# CC3200 register map
Vendor: Texas Instruments; Series: SimpleLink; File version: 1.0
CPU: CM4 r0p1, little endian, MPU, no FPU, 3 interrupt priority bits
Registers are 32-bit, read-write, reset 0x0 unless marked. A register's access mark holds for its fields unless they carry their own. Offsets are from the block's base; [hi:lo] are bit positions; {n}, {i} and the like mark numbered series.

## MMCHS — SDHOST
Base 0x44010000
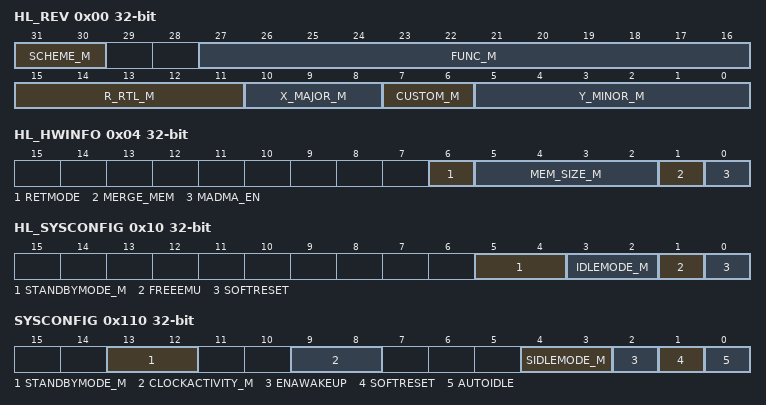
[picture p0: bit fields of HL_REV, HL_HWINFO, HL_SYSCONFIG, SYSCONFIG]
0x00 HL_REV — MMCHS_HL_REV
  [31:30] SCHEME_M — MMCHS_HL_REV
  [27:16] FUNC_M — MMCHS_HL_REV
  [15:11] R_RTL_M — MMCHS_HL_REV
  [10:8] X_MAJOR_M — MMCHS_HL_REV
  [7:6] CUSTOM_M — MMCHS_HL_REV
  [5:0] Y_MINOR_M — MMCHS_HL_REV
0x04 HL_HWINFO — MMCHS_HL_HWINFO
  [6] RETMODE — MMCHS_HL_HWINFO
  [5:2] MEM_SIZE_M — MMCHS_HL_HWINFO
  [1] MERGE_MEM — MMCHS_HL_HWINFO
  [0] MADMA_EN — MMCHS_HL_HWINFO
0x10 HL_SYSCONFIG — MMCHS_HL_SYSCONFIG
  [5:4] STANDBYMODE_M — MMCHS_HL_SYSCONFIG
  [3:2] IDLEMODE_M — MMCHS_HL_SYSCONFIG
  [1] FREEEMU — MMCHS_HL_SYSCONFIG
  [0] SOFTRESET — MMCHS_HL_SYSCONFIG
0x110 SYSCONFIG — MMCHS_SYSCONFIG
  [13:12] STANDBYMODE_M — MMCHS_SYSCONFIG
  [9:8] CLOCKACTIVITY_M — MMCHS_SYSCONFIG
  [4:3] SIDLEMODE_M — MMCHS_SYSCONFIG
  [2] ENAWAKEUP — MMCHS_SYSCONFIG
  [1] SOFTRESET — MMCHS_SYSCONFIG
  [0] AUTOIDLE — MMCHS_SYSCONFIG
0x114 SYSSTATUS — MMCHS_SYSSTATUS
  [0] RESETDONE
0x124 CSRE — MMCHS_CSRE
  [31:0] CSRE_M
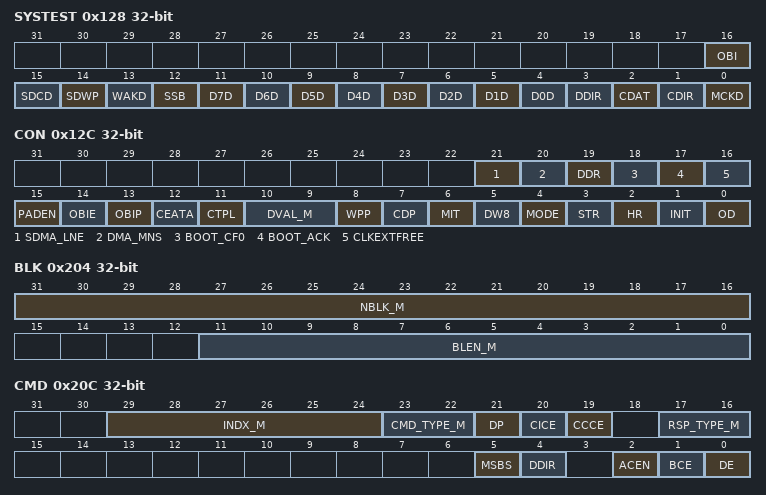
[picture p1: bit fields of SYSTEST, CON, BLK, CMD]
0x128 SYSTEST — MMCHS_SYSTEST
  [16] OBI — MMCHS_SYSTEST
  [15] SDCD — MMCHS_SYSTEST
  [14] SDWP — MMCHS_SYSTEST
  [13] WAKD — MMCHS_SYSTEST
  [12] SSB — MMCHS_SYSTEST
  [n+4] D{n}D (n=0..7) — MMCHS_SYSTEST
  [3] DDIR — MMCHS_SYSTEST
  [2] CDAT — MMCHS_SYSTEST
  [1] CDIR — MMCHS_SYSTEST
  [0] MCKD — MMCHS_SYSTEST
0x12C CON — MMCHS_CON
  [21] SDMA_LNE — MMCHS_CON
  [20] DMA_MNS — MMCHS_CON
  [19] DDR — MMCHS_CON
  [18] BOOT_CF0 — MMCHS_CON
  [17] BOOT_ACK — MMCHS_CON
  [16] CLKEXTFREE — MMCHS_CON
  [15] PADEN — MMCHS_CON
  [14] OBIE — MMCHS_CON
  [13] OBIP — MMCHS_CON
  [12] CEATA — MMCHS_CON
  [11] CTPL — MMCHS_CON
  [10:9] DVAL_M — MMCHS_CON
  [8] WPP — MMCHS_CON
  [7] CDP — MMCHS_CON
  [6] MIT — MMCHS_CON
  [5] DW8 — MMCHS_CON
  [4] MODE — MMCHS_CON
  [3] STR — MMCHS_CON
  [2] HR — MMCHS_CON
  [1] INIT — MMCHS_CON
  [0] OD — MMCHS_CON
0x130 PWCNT — MMCHS_PWCNT
  [15:0] PWRCNT_M
0x204 BLK — MMCHS_BLK
  [31:16] NBLK_M — MMCHS_BLK
  [11:0] BLEN_M — MMCHS_BLK
0x208 ARG — MMCHS_ARG
  [31:0] ARG_M
0x20C CMD — MMCHS_CMD
  [29:24] INDX_M — MMCHS_CMD
  [23:22] CMD_TYPE_M — MMCHS_CMD
  [21] DP — MMCHS_CMD
  [20] CICE — MMCHS_CMD
  [19] CCCE — MMCHS_CMD
  [17:16] RSP_TYPE_M — MMCHS_CMD
  [5] MSBS — MMCHS_CMD
  [4] DDIR — MMCHS_CMD
  [2] ACEN — MMCHS_CMD
  [1] BCE — MMCHS_CMD
  [0] DE — MMCHS_CMD
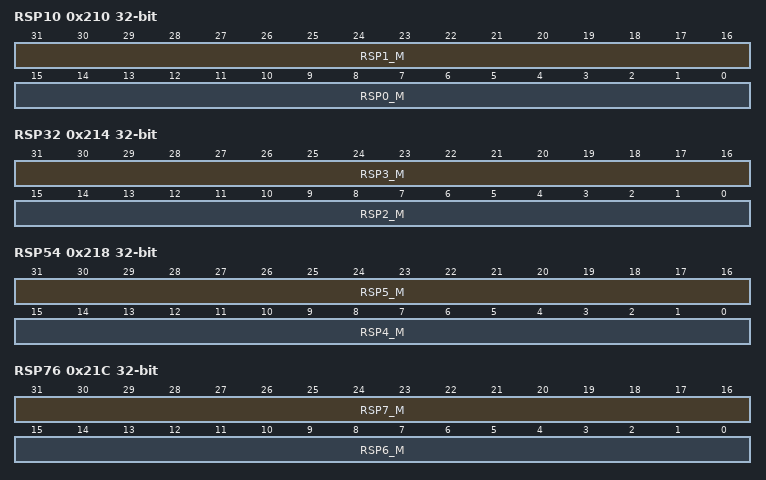
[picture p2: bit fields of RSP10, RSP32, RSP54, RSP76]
0x210 RSP10 — MMCHS_RSP10
  [31:16] RSP1_M — MMCHS_RSP10
  [15:0] RSP0_M — MMCHS_RSP10
0x214 RSP32 — MMCHS_RSP32
  [31:16] RSP3_M — MMCHS_RSP32
  [15:0] RSP2_M — MMCHS_RSP32
0x218 RSP54 — MMCHS_RSP54
  [31:16] RSP5_M — MMCHS_RSP54
  [15:0] RSP4_M — MMCHS_RSP54
0x21C RSP76 — MMCHS_RSP76
  [31:16] RSP7_M — MMCHS_RSP76
  [15:0] RSP6_M — MMCHS_RSP76
0x220 DATA — MMCHS_DATA
  [31:0] DATA_M
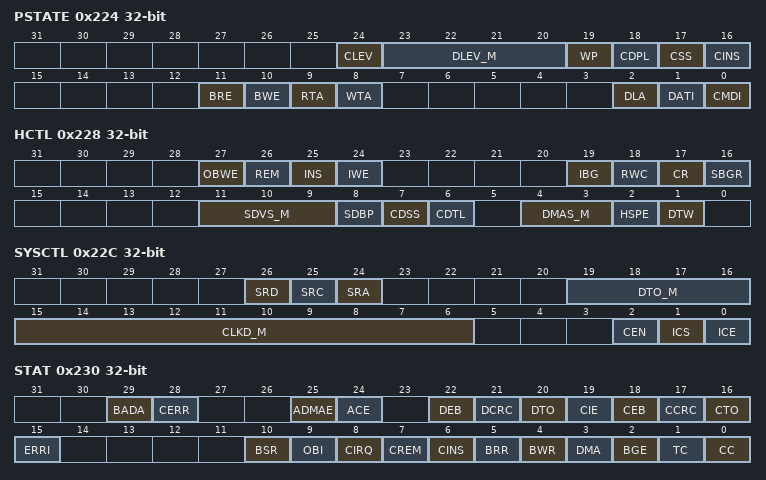
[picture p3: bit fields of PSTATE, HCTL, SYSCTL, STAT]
0x224 PSTATE — MMCHS_PSTATE
  [24] CLEV — MMCHS_PSTATE
  [23:20] DLEV_M — MMCHS_PSTATE
  [19] WP — MMCHS_PSTATE
  [18] CDPL — MMCHS_PSTATE
  [17] CSS — MMCHS_PSTATE
  [16] CINS — MMCHS_PSTATE
  [11] BRE — MMCHS_PSTATE
  [10] BWE — MMCHS_PSTATE
  [9] RTA — MMCHS_PSTATE
  [8] WTA — MMCHS_PSTATE
  [2] DLA — MMCHS_PSTATE
  [1] DATI — MMCHS_PSTATE
  [0] CMDI — MMCHS_PSTATE
0x228 HCTL — MMCHS_HCTL
  [27] OBWE — MMCHS_HCTL
  [26] REM — MMCHS_HCTL
  [25] INS — MMCHS_HCTL
  [24] IWE — MMCHS_HCTL
  [19] IBG — MMCHS_HCTL
  [18] RWC — MMCHS_HCTL
  [17] CR — MMCHS_HCTL
  [16] SBGR — MMCHS_HCTL
  [11:9] SDVS_M — MMCHS_HCTL
  [8] SDBP — MMCHS_HCTL
  [7] CDSS — MMCHS_HCTL
  [6] CDTL — MMCHS_HCTL
  [4:3] DMAS_M — MMCHS_HCTL
  [2] HSPE — MMCHS_HCTL
  [1] DTW — MMCHS_HCTL
0x22C SYSCTL — MMCHS_SYSCTL
  [26] SRD — MMCHS_SYSCTL
  [25] SRC — MMCHS_SYSCTL
  [24] SRA — MMCHS_SYSCTL
  [19:16] DTO_M — MMCHS_SYSCTL
  [15:6] CLKD_M — MMCHS_SYSCTL
  [2] CEN — MMCHS_SYSCTL
  [1] ICS — MMCHS_SYSCTL
  [0] ICE — MMCHS_SYSCTL
0x230 STAT — MMCHS_STAT
  [29] BADA — MMCHS_STAT
  [28] CERR — MMCHS_STAT
  [25] ADMAE — MMCHS_STAT
  [24] ACE — MMCHS_STAT
  [22] DEB — MMCHS_STAT
  [21] DCRC — MMCHS_STAT
  [20] DTO — MMCHS_STAT
  [19] CIE — MMCHS_STAT
  [18] CEB — MMCHS_STAT
  [17] CCRC — MMCHS_STAT
  [16] CTO — MMCHS_STAT
  [15] ERRI — MMCHS_STAT
  [10] BSR — MMCHS_STAT
  [9] OBI — MMCHS_STAT
  [8] CIRQ — MMCHS_STAT
  [7] CREM — MMCHS_STAT
  [6] CINS — MMCHS_STAT
  [5] BRR — MMCHS_STAT
  [4] BWR — MMCHS_STAT
  [3] DMA — MMCHS_STAT
  [2] BGE — MMCHS_STAT
  [1] TC — MMCHS_STAT
  [0] CC — MMCHS_STAT
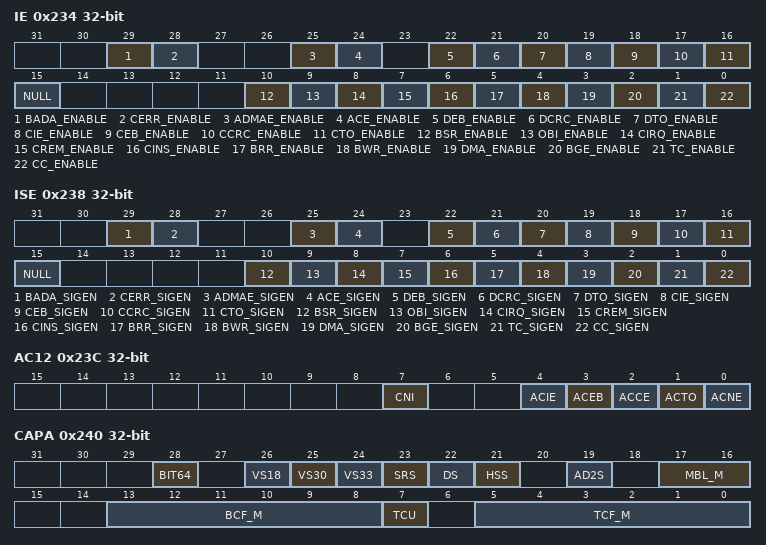
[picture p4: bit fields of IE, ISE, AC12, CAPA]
0x234 IE — MMCHS_IE
  [29] BADA_ENABLE — MMCHS_IE
  [28] CERR_ENABLE — MMCHS_IE
  [25] ADMAE_ENABLE — MMCHS_IE
  [24] ACE_ENABLE — MMCHS_IE
  [22] DEB_ENABLE — MMCHS_IE
  [21] DCRC_ENABLE — MMCHS_IE
  [20] DTO_ENABLE — MMCHS_IE
  [19] CIE_ENABLE — MMCHS_IE
  [18] CEB_ENABLE — MMCHS_IE
  [17] CCRC_ENABLE — MMCHS_IE
  [16] CTO_ENABLE — MMCHS_IE
  [15] NULL — MMCHS_IE
  [10] BSR_ENABLE — MMCHS_IE
  [9] OBI_ENABLE — MMCHS_IE
  [8] CIRQ_ENABLE — MMCHS_IE
  [7] CREM_ENABLE — MMCHS_IE
  [6] CINS_ENABLE — MMCHS_IE
  [5] BRR_ENABLE — MMCHS_IE
  [4] BWR_ENABLE — MMCHS_IE
  [3] DMA_ENABLE — MMCHS_IE
  [2] BGE_ENABLE — MMCHS_IE
  [1] TC_ENABLE — MMCHS_IE
  [0] CC_ENABLE — MMCHS_IE
0x238 ISE — MMCHS_ISE
  [29] BADA_SIGEN — MMCHS_ISE
  [28] CERR_SIGEN — MMCHS_ISE
  [25] ADMAE_SIGEN — MMCHS_ISE
  [24] ACE_SIGEN — MMCHS_ISE
  [22] DEB_SIGEN — MMCHS_ISE
  [21] DCRC_SIGEN — MMCHS_ISE
  [20] DTO_SIGEN — MMCHS_ISE
  [19] CIE_SIGEN — MMCHS_ISE
  [18] CEB_SIGEN — MMCHS_ISE
  [17] CCRC_SIGEN — MMCHS_ISE
  [16] CTO_SIGEN — MMCHS_ISE
  [15] NULL — MMCHS_ISE
  [10] BSR_SIGEN — MMCHS_ISE
  [9] OBI_SIGEN — MMCHS_ISE
  [8] CIRQ_SIGEN — MMCHS_ISE
  [7] CREM_SIGEN — MMCHS_ISE
  [6] CINS_SIGEN — MMCHS_ISE
  [5] BRR_SIGEN — MMCHS_ISE
  [4] BWR_SIGEN — MMCHS_ISE
  [3] DMA_SIGEN — MMCHS_ISE
  [2] BGE_SIGEN — MMCHS_ISE
  [1] TC_SIGEN — MMCHS_ISE
  [0] CC_SIGEN — MMCHS_ISE
0x23C AC12 — MMCHS_AC12
  [7] CNI — MMCHS_AC12
  [4] ACIE — MMCHS_AC12
  [3] ACEB — MMCHS_AC12
  [2] ACCE — MMCHS_AC12
  [1] ACTO — MMCHS_AC12
  [0] ACNE — MMCHS_AC12
0x240 CAPA — MMCHS_CAPA
  [28] BIT64 — MMCHS_CAPA
  [26] VS18 — MMCHS_CAPA
  [25] VS30 — MMCHS_CAPA
  [24] VS33 — MMCHS_CAPA
  [23] SRS — MMCHS_CAPA
  [22] DS — MMCHS_CAPA
  [21] HSS — MMCHS_CAPA
  [19] AD2S — MMCHS_CAPA
  [17:16] MBL_M — MMCHS_CAPA
  [13:8] BCF_M — MMCHS_CAPA
  [7] TCU — MMCHS_CAPA
  [5:0] TCF_M — MMCHS_CAPA
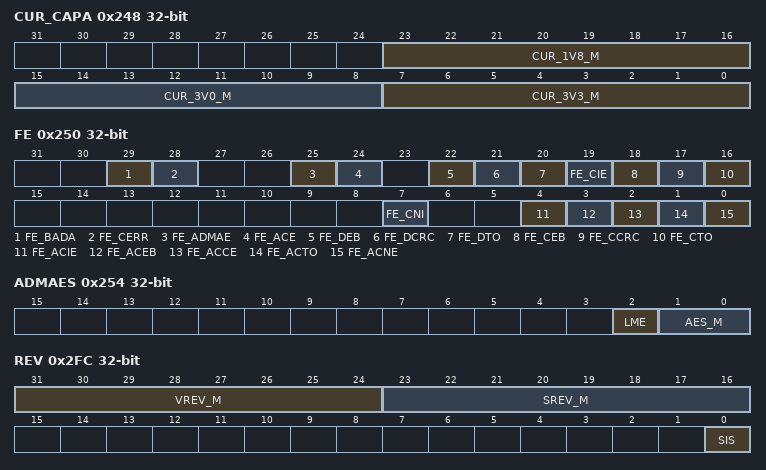
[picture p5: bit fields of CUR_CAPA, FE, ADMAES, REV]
0x248 CUR_CAPA — MMCHS_CUR_CAPA
  [23:16] CUR_1V8_M — MMCHS_CUR_CAPA
  [15:8] CUR_3V0_M — MMCHS_CUR_CAPA
  [7:0] CUR_3V3_M — MMCHS_CUR_CAPA
0x250 FE — MMCHS_FE
  [29] FE_BADA — MMCHS_FE
  [28] FE_CERR — MMCHS_FE
  [25] FE_ADMAE — MMCHS_FE
  [24] FE_ACE — MMCHS_FE
  [22] FE_DEB — MMCHS_FE
  [21] FE_DCRC — MMCHS_FE
  [20] FE_DTO — MMCHS_FE
  [19] FE_CIE — MMCHS_FE
  [18] FE_CEB — MMCHS_FE
  [17] FE_CCRC — MMCHS_FE
  [16] FE_CTO — MMCHS_FE
  [7] FE_CNI — MMCHS_FE
  [4] FE_ACIE — MMCHS_FE
  [3] FE_ACEB — MMCHS_FE
  [2] FE_ACCE — MMCHS_FE
  [1] FE_ACTO — MMCHS_FE
  [0] FE_ACNE — MMCHS_FE
0x254 ADMAES — MMCHS_ADMAES
  [2] LME — MMCHS_ADMAES
  [1:0] AES_M — MMCHS_ADMAES
0x258 ADMASAL — MMCHS_ADMASAL
  [31:0] ADMA_A32B_M
0x2FC REV — MMCHS_REV
  [31:24] VREV_M — MMCHS_REV
  [23:16] SREV_M — MMCHS_REV
  [0] SIS — MMCHS_REV
